AUTOSAR XML (schema 4-2-2)
package /Components
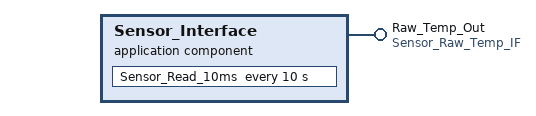
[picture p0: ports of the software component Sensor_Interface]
  application sw component type Sensor_Interface
    provide port Raw_Temp_Out: provided-interface=Sensor_Raw_Temp_IF
    behavior Sensor_Interface_InternalBehavior
      init event Sensor_Init_Event: start-on-event=Sensor_Read_10ms
      timing event Sensor_10ms_Event: start-on-event=Sensor_Read_10ms, period=10
      runnable Sensor_Read_10ms: minimum-start-interval=10
        data-send-points:
          access VA_Temp{1..3}_Raw: accessed-variable=Raw_Temp_Out.Temp{1..3}_Raw
